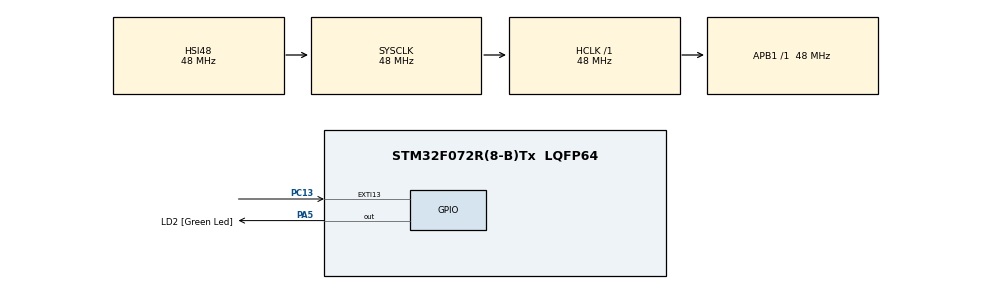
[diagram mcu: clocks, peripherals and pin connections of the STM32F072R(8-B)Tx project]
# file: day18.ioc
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Mcu.Family=STM32F0
Mcu.Name=STM32F072R(8-B)Tx
Mcu.Package=LQFP64
NVIC.EXTI4_15_IRQn=true\:0\:0\:false\:false\:true\:true\:true\:true
PA14.GPIO_Label=TCK
PA14.Signal=SYS_SWCLK
PA5.GPIO_Label=LD2 [Green Led]
PA5.GPIO_Mode=GPIO_MODE_OUTPUT_PP
PA5.GPIO_PuPd=GPIO_NOPULL
PA5.GPIO_Speed=GPIO_SPEED_FREQ_LOW
PA5.Signal=GPIO_Output
PC13.Signal=GPXTI13
ProjectManager.HeapSize=0x200
ProjectManager.StackSize=0x400
ProjectManager.TargetToolchain=STM32CubeIDE
RCC.AHBFreq_Value=48000000
RCC.APB1Freq_Value=48000000
RCC.APB1TimFreq_Value=48000000
RCC.FLatency-AdvancedSettings=FLASH_LATENCY_1
RCC.HCLKFreq_Value=48000000
RCC.PLLDivider=RCC_PREDIV_DIV2
RCC.PLLMUL=RCC_PLL_MUL12
RCC.PREFETCH_ENABLE-AdvancedSettings=1
RCC.SYSCLKFreq_VALUE=48000000
RCC.SYSCLKSource=RCC_SYSCLKSOURCE_HSI48
board=NUCLEO-F072RB

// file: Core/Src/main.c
/* USER CODE BEGIN Header */
/**
  ******************************************************************************
  * @file           : main.c
  * @brief          : Main program body
  ******************************************************************************
  * @attention
  *
  * Copyright (c) 2026 STMicroelectronics.
  * All rights reserved.
  *
  * This software is licensed under terms that can be found in the LICENSE file
  * in the root directory of this software component.
  * If no LICENSE file comes with this software, it is provided AS-IS.
  *
  ******************************************************************************
  */
/* USER CODE END Header */
#include "main.h"

/* USER CODE BEGIN PD */
#define BUTTON_DEBOUNCE_MS 50U

/* USER CODE END PD */

/* USER CODE BEGIN PV */
volatile uint8_t button_event = 0U;
uint32_t last_button_time = 0U;

/* USER CODE END PV */

void SystemClock_Config(void);
static void MX_GPIO_Init(void);

int main(void)
{

  /* MCU Configuration--------------------------------------------------------*/

  /* Reset of all peripherals, Initializes the Flash interface and the Systick. */
  HAL_Init();

  /* Configure the system clock */
  SystemClock_Config();

  /* Initialize all configured peripherals */
  MX_GPIO_Init();

  /* Infinite loop */
  while (1)
  {
	  if (button_event != 0U)
	      {
	          button_event = 0U;
	          uint32_t current_time = HAL_GetTick();

	          if((current_time - last_button_time) > BUTTON_DEBOUNCE_MS)
	          {
	        	  last_button_time = current_time;
	        	  HAL_GPIO_TogglePin(GPIOA, GPIO_PIN_5);
	          }

	      }

  }
}

void SystemClock_Config(void)
{
  RCC_OscInitTypeDef RCC_OscInitStruct = {0};
  RCC_ClkInitTypeDef RCC_ClkInitStruct = {0};

  /** Initializes the RCC Oscillators according to the specified parameters
  * in the RCC_OscInitTypeDef structure.
  */
  RCC_OscInitStruct.OscillatorType = RCC_OSCILLATORTYPE_HSI48;
  RCC_OscInitStruct.HSI48State = RCC_HSI48_ON;
  RCC_OscInitStruct.PLL.PLLState = RCC_PLL_NONE;
  if (HAL_RCC_OscConfig(&RCC_OscInitStruct) != HAL_OK)
  {
    Error_Handler();
  }

  /** Initializes the CPU, AHB and APB buses clocks
  */
  RCC_ClkInitStruct.ClockType = RCC_CLOCKTYPE_HCLK|RCC_CLOCKTYPE_SYSCLK
                              |RCC_CLOCKTYPE_PCLK1;
  RCC_ClkInitStruct.SYSCLKSource = RCC_SYSCLKSOURCE_HSI48;
  RCC_ClkInitStruct.AHBCLKDivider = RCC_SYSCLK_DIV1;
  RCC_ClkInitStruct.APB1CLKDivider = RCC_HCLK_DIV1;

  if (HAL_RCC_ClockConfig(&RCC_ClkInitStruct, FLASH_LATENCY_1) != HAL_OK)
  {
    Error_Handler();
  }
}

static void MX_GPIO_Init(void)
{
  GPIO_InitTypeDef GPIO_InitStruct = {0};

  /* GPIO Ports Clock Enable */
  __HAL_RCC_GPIOC_CLK_ENABLE();
  __HAL_RCC_GPIOA_CLK_ENABLE();

  /*Configure GPIO pin Output Level */
  HAL_GPIO_WritePin(LD2_GPIO_Port, LD2_Pin, GPIO_PIN_RESET);

  /*Configure GPIO pin : PC13 */
  GPIO_InitStruct.Pin = GPIO_PIN_13;
  GPIO_InitStruct.Mode = GPIO_MODE_IT_RISING;
  GPIO_InitStruct.Pull = GPIO_NOPULL;
  HAL_GPIO_Init(GPIOC, &GPIO_InitStruct);

  /*Configure GPIO pin : LD2_Pin */
  GPIO_InitStruct.Pin = LD2_Pin;
  GPIO_InitStruct.Mode = GPIO_MODE_OUTPUT_PP;
  GPIO_InitStruct.Pull = GPIO_NOPULL;
  GPIO_InitStruct.Speed = GPIO_SPEED_FREQ_LOW;
  HAL_GPIO_Init(LD2_GPIO_Port, &GPIO_InitStruct);

  /* EXTI interrupt init*/
  HAL_NVIC_SetPriority(EXTI4_15_IRQn, 0, 0);
  HAL_NVIC_EnableIRQ(EXTI4_15_IRQn);

}

void Error_Handler(void)
{
  __disable_irq();
  while (1)
  {
  }
}

/* handler */
void HAL_GPIO_EXTI_Callback(uint16_t GPIO_Pin)
{
    if (GPIO_Pin == GPIO_PIN_13)
    {
        button_event = 1U;
    }
}
